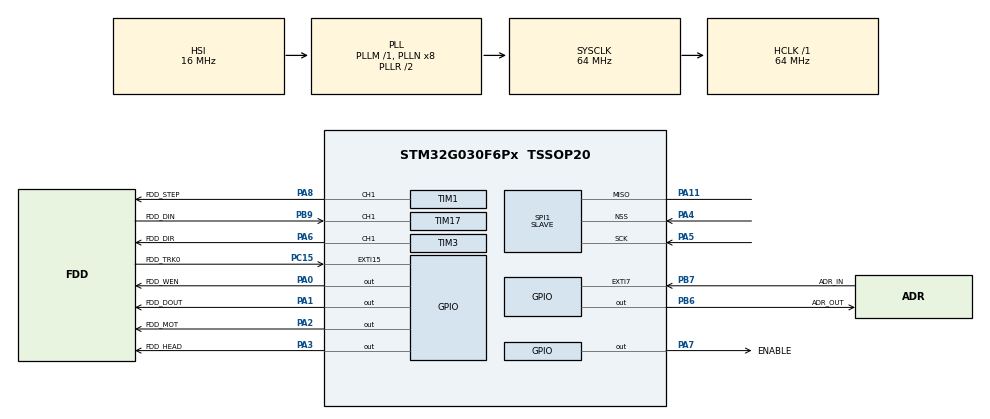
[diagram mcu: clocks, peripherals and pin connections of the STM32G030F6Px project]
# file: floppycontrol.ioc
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Dma.MEMTOMEM.3.Direction=DMA_MEMORY_TO_MEMORY
Dma.MEMTOMEM.3.EventEnable=DISABLE
Dma.MEMTOMEM.3.Instance=DMA1_Channel4
Dma.MEMTOMEM.3.MemDataAlignment=DMA_MDATAALIGN_BYTE
Dma.MEMTOMEM.3.MemInc=DMA_MINC_ENABLE
Dma.MEMTOMEM.3.Mode=DMA_NORMAL
Dma.MEMTOMEM.3.PeriphDataAlignment=DMA_PDATAALIGN_BYTE
Dma.MEMTOMEM.3.PeriphInc=DMA_PINC_ENABLE
Dma.MEMTOMEM.3.Polarity=HAL_DMAMUX_REQ_GEN_RISING
Dma.MEMTOMEM.3.Priority=DMA_PRIORITY_LOW
Dma.MEMTOMEM.3.RequestNumber=1
Dma.MEMTOMEM.3.SignalID=NONE
Dma.MEMTOMEM.3.SyncEnable=DISABLE
Dma.MEMTOMEM.3.SyncPolarity=HAL_DMAMUX_SYNC_NO_EVENT
Dma.MEMTOMEM.3.SyncRequestNumber=1
Dma.MEMTOMEM.3.SyncSignalID=NONE
Dma.Request0=SPI1_RX
Dma.Request1=SPI1_TX
Dma.Request2=TIM17_CH1
Dma.Request3=MEMTOMEM
Dma.SPI1_RX.0.Direction=DMA_PERIPH_TO_MEMORY
Dma.SPI1_RX.0.EventEnable=DISABLE
Dma.SPI1_RX.0.Instance=DMA1_Channel1
Dma.SPI1_RX.0.MemDataAlignment=DMA_MDATAALIGN_BYTE
Dma.SPI1_RX.0.MemInc=DMA_MINC_ENABLE
Dma.SPI1_RX.0.Mode=DMA_NORMAL
Dma.SPI1_RX.0.PeriphDataAlignment=DMA_PDATAALIGN_BYTE
Dma.SPI1_RX.0.PeriphInc=DMA_PINC_DISABLE
Dma.SPI1_RX.0.Polarity=HAL_DMAMUX_REQ_GEN_RISING
Dma.SPI1_RX.0.Priority=DMA_PRIORITY_LOW
Dma.SPI1_RX.0.RequestNumber=1
Dma.SPI1_RX.0.SignalID=NONE
Dma.SPI1_RX.0.SyncEnable=DISABLE
Dma.SPI1_RX.0.SyncPolarity=HAL_DMAMUX_SYNC_NO_EVENT
Dma.SPI1_RX.0.SyncRequestNumber=1
Dma.SPI1_RX.0.SyncSignalID=NONE
Dma.SPI1_TX.1.Direction=DMA_MEMORY_TO_PERIPH
Dma.SPI1_TX.1.EventEnable=DISABLE
Dma.SPI1_TX.1.Instance=DMA1_Channel2
Dma.SPI1_TX.1.MemDataAlignment=DMA_MDATAALIGN_BYTE
Dma.SPI1_TX.1.MemInc=DMA_MINC_ENABLE
Dma.SPI1_TX.1.Mode=DMA_NORMAL
Dma.SPI1_TX.1.PeriphDataAlignment=DMA_PDATAALIGN_BYTE
Dma.SPI1_TX.1.PeriphInc=DMA_PINC_DISABLE
Dma.SPI1_TX.1.Polarity=HAL_DMAMUX_REQ_GEN_RISING
Dma.SPI1_TX.1.Priority=DMA_PRIORITY_LOW
Dma.SPI1_TX.1.RequestNumber=1
Dma.SPI1_TX.1.SignalID=NONE
Dma.SPI1_TX.1.SyncEnable=DISABLE
Dma.SPI1_TX.1.SyncPolarity=HAL_DMAMUX_SYNC_NO_EVENT
Dma.SPI1_TX.1.SyncRequestNumber=1
Dma.SPI1_TX.1.SyncSignalID=NONE
Dma.TIM17_CH1.2.Direction=DMA_PERIPH_TO_MEMORY
Dma.TIM17_CH1.2.EventEnable=DISABLE
Dma.TIM17_CH1.2.Instance=DMA1_Channel3
Dma.TIM17_CH1.2.MemDataAlignment=DMA_MDATAALIGN_HALFWORD
Dma.TIM17_CH1.2.MemInc=DMA_MINC_ENABLE
Dma.TIM17_CH1.2.Mode=DMA_CIRCULAR
Dma.TIM17_CH1.2.PeriphDataAlignment=DMA_PDATAALIGN_HALFWORD
Dma.TIM17_CH1.2.PeriphInc=DMA_PINC_DISABLE
Dma.TIM17_CH1.2.Polarity=HAL_DMAMUX_REQ_GEN_RISING
Dma.TIM17_CH1.2.Priority=DMA_PRIORITY_LOW
Dma.TIM17_CH1.2.RequestNumber=1
Dma.TIM17_CH1.2.SignalID=NONE
Dma.TIM17_CH1.2.SyncEnable=DISABLE
Dma.TIM17_CH1.2.SyncPolarity=HAL_DMAMUX_SYNC_NO_EVENT
Dma.TIM17_CH1.2.SyncRequestNumber=1
Dma.TIM17_CH1.2.SyncSignalID=NONE
Mcu.Family=STM32G0
Mcu.Name=STM32G030F6Px
Mcu.Package=TSSOP20
NVIC.DMA1_Channel1_IRQn=true\:0\:0\:false\:false\:true\:false\:true\:true
NVIC.DMA1_Channel2_3_IRQn=true\:1\:0\:true\:false\:true\:false\:true\:true
NVIC.EXTI4_15_IRQn=true\:2\:0\:true\:false\:true\:true\:true\:true
NVIC.SPI1_IRQn=true\:1\:0\:true\:false\:true\:true\:true\:true
NVIC.TIM17_IRQn=true\:2\:0\:true\:false\:true\:true\:true\:true
PA0.GPIO_Label=FDD_WEN
PA0.GPIO_ModeDefaultOutputPP=GPIO_MODE_OUTPUT_OD
PA0.GPIO_PuPd=GPIO_NOPULL
PA0.PinState=GPIO_PIN_SET
PA0.Signal=GPIO_Output
PA1.GPIO_Label=FDD_DOUT
PA1.GPIO_ModeDefaultOutputPP=GPIO_MODE_OUTPUT_OD
PA1.GPIO_PuPd=GPIO_NOPULL
PA1.PinState=GPIO_PIN_SET
PA1.Signal=GPIO_Output
PA11\ [PA9].GPIO_Speed=GPIO_SPEED_FREQ_HIGH
PA11\ [PA9].Mode=Simplex_Bidirectional_Slave
PA11\ [PA9].Signal=SPI1_MISO
PA12\ [PA10].GPIO_Label=EXTCLK
PA12\ [PA10].Signal=S_TIM1_ETR
PA13.GPIO_Label=SWD_IDX
PA13.Mode=Serial_Wire
PA13.Signal=SYS_SWDIO
PA14-BOOT0.Mode=Serial_Wire
PA14-BOOT0.Signal=SYS_SWCLK
PA14-BOOT0__PA15.StandardMode=false
PA2.GPIO_Label=FDD_MOT
PA2.GPIO_ModeDefaultOutputPP=GPIO_MODE_OUTPUT_OD
PA2.GPIO_PuPd=GPIO_NOPULL
PA2.PinState=GPIO_PIN_SET
PA2.Signal=GPIO_Output
PA3.GPIO_Label=FDD_HEAD
PA3.GPIO_ModeDefaultOutputPP=GPIO_MODE_OUTPUT_OD
PA3.GPIO_PuPd=GPIO_NOPULL
PA3.PinState=GPIO_PIN_SET
PA3.Signal=GPIO_Output
PA4.GPIO_Speed=GPIO_SPEED_FREQ_HIGH
PA4.Mode=NSS_Signal_Hard_Input
PA4.Signal=SPI1_NSS
PA5.GPIO_Speed=GPIO_SPEED_FREQ_HIGH
PA5.Mode=Simplex_Bidirectional_Slave
PA5.Signal=SPI1_SCK
PA6.GPIO_Label=FDD_DIR
PA6.GPIO_ModeDefaultPP=GPIO_MODE_AF_OD
PA6.GPIO_Speed=GPIO_SPEED_FREQ_HIGH
PA6.Signal=S_TIM3_CH1
PA7.GPIO_Label=ENABLE
PA7.GPIO_ModeDefaultOutputPP=GPIO_MODE_OUTPUT_OD
PA7.GPIO_PuPd=GPIO_PULLUP
PA7.GPIO_Speed=GPIO_SPEED_FREQ_HIGH
PA7.PinState=GPIO_PIN_SET
PA7.Signal=GPIO_Output
PA8.GPIO_Label=FDD_STEP
PA8.GPIO_ModeDefaultPP=GPIO_MODE_AF_OD
PA8.GPIO_Speed=GPIO_SPEED_FREQ_HIGH
PA8.PinState=GPIO_PIN_RESET
PA8.Signal=S_TIM1_CH1
PB0__PB1__PB2__PA8.StandardMode=true
PB3__PB4__PB5__PB6.StandardMode=true
PB6.GPIO_Label=ADR_OUT
PB6.GPIO_Speed=GPIO_SPEED_FREQ_MEDIUM
PB6.Signal=GPIO_Output
PB7.GPIO_Label=ADR_IN
PB7.GPIO_ModeDefaultEXTI=GPIO_MODE_IT_RISING_FALLING
PB7.GPIO_PuPd=GPIO_PULLUP
PB7.Signal=GPXTI7
PB7__PB8.StandardMode=true
PB9.GPIO_FM9=SYSCFG_FASTMODEPLUS_PB9
PB9.GPIO_Label=FDD_DIN
PB9.GPIO_ModeDefaultPP=GPIO_MODE_AF_OD
PB9.GPIO_PuPd=GPIO_PULLUP
PB9.Signal=S_TIM17_CH1
PC14-OSC32_IN\ (PC14)__PB9.StandardMode=true
PC15-OSC32_OUT\ (PC15).GPIO_Label=FDD_TRK0
PC15-OSC32_OUT\ (PC15).GPIO_ModeDefaultEXTI=GPIO_MODE_IT_FALLING
PC15-OSC32_OUT\ (PC15).GPIO_PuPd=GPIO_PULLUP
PC15-OSC32_OUT\ (PC15).Signal=GPXTI15
ProjectManager.HeapSize=0x200
ProjectManager.StackSize=0x400
ProjectManager.TargetToolchain=STM32CubeIDE
RCC.ADCFreq_Value=64000000
RCC.AHBFreq_Value=64000000
RCC.CortexFreq_Value=64000000
RCC.EXTERNAL_CLOCK_VALUE=12288000
RCC.HCLKFreq_Value=64000000
RCC.HSE_VALUE=8000000
RCC.HSI_VALUE=16000000
RCC.LSE_VALUE=32768
RCC.SYSCLKFreq_VALUE=64000000
RCC.SYSCLKSource=RCC_SYSCLKSOURCE_PLLCLK
RCC.VCOOutputFreq_Value=128000000
SH.S_TIM17_CH1.0=TIM17_CH1,Input_Capture1_from_TI1
SH.S_TIM1_CH1.0=TIM1_CH1,PWM Generation1 CH1
SH.S_TIM1_ETR.0=TIM1_ETR
SH.S_TIM3_CH1.0=TIM3_CH1,PWM Generation1 CH1
SPI1.CLKPhase=SPI_PHASE_1EDGE
SPI1.CLKPolarity=SPI_POLARITY_LOW
SPI1.CRCCalculation=SPI_CRCCALCULATION_ENABLE
SPI1.CRCLength=SPI_CRC_LENGTH_DATASIZE
SPI1.Direction=SPI_DIRECTION_1LINE
SPI1.FirstBit=SPI_FIRSTBIT_MSB
SPI1.Mode=SPI_MODE_SLAVE
SPI1.VirtualNSS=VM_NSSHARD
SPI1.VirtualType=VM_SLAVE
TIM1.Channel-PWM\ Generation1\ CH1=TIM_CHANNEL_1
TIM1.Period=64000
TIM1.Pulse-PWM\ Generation1\ CH1=5000
TIM1.TIM_MasterOutputTrigger=TIM_TRGO_UPDATE
TIM14.Period=100
TIM14.Prescaler=64000
TIM17.AutoReloadPreload=TIM_AUTORELOAD_PRELOAD_ENABLE
TIM17.Channel=TIM_CHANNEL_1
TIM17.Prescaler=15
TIM3.Channel-PWM\ Generation1\ CH1=TIM_CHANNEL_1
TIM3.OCPolarity_1=TIM_OCPOLARITY_LOW
TIM3.Period=160-1
TIM3.Pulse-PWM\ Generation1\ CH1=80
VP_TIM14_VS_ClockSourceINT.Mode=Enable_Timer
VP_TIM17_VS_ClockSourceINT.Mode=Enable_Timer
VP_TIM1_VS_ClockSourceINT.Mode=Internal
VP_TIM3_VS_ClockSourceITR.Mode=TriggerSource_ITR0
VP_TIM3_VS_ControllerModeClock.Mode=Clock Mode
board=custom

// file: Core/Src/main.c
/* USER CODE BEGIN Header */
/**
  ******************************************************************************
  * @file           : main.c
  * @brief          : Main program body
  ******************************************************************************
  * @attention
  *
  * Copyright (c) 2022 STMicroelectronics.
  * All rights reserved.
  *
  * This software is licensed under terms that can be found in the LICENSE file
  * in the root directory of this software component.
  * If no LICENSE file comes with this software, it is provided AS-IS.
  *
  ******************************************************************************
  */
/* USER CODE END Header */
#include "main.h"

/* USER CODE BEGIN Includes */
#include "floppyctrl.h"
/* USER CODE END Includes */

 SPI_HandleTypeDef hspi1;
DMA_HandleTypeDef hdma_spi1_rx;
DMA_HandleTypeDef hdma_spi1_tx;

TIM_HandleTypeDef htim1;
TIM_HandleTypeDef htim3;
TIM_HandleTypeDef htim14;
TIM_HandleTypeDef htim17;
DMA_HandleTypeDef hdma_tim17_ch1;

DMA_HandleTypeDef hdma_memtomem_dma1_channel4;

void SystemClock_Config(void);
static void MX_GPIO_Init(void);
static void MX_DMA_Init(void);
static void MX_SPI1_Init(void);
static void MX_TIM14_Init(void);
static void MX_TIM17_Init(void);

int main(void)
{

  /* MCU Configuration--------------------------------------------------------*/

  /* Reset of all peripherals, Initializes the Flash interface and the Systick. */
  HAL_Init();

  /* Configure the system clock */
  SystemClock_Config();

  /* USER CODE BEGIN SysInit */
  HAL_Delay(1000); // Allow some time for the debugger
  /* USER CODE END SysInit */

  /* Initialize all configured peripherals */
  MX_GPIO_Init();
  MX_DMA_Init();
  MX_SPI1_Init();
  MX_TIM1_Init();
  MX_TIM3_Init();
  MX_TIM14_Init();
  MX_TIM17_Init();
  /* USER CODE BEGIN 2 */
  // Set DIN pin to pullup
//  GPIO_InitTypeDef GPIO_InitStruct = {0};
//  GPIO_InitStruct.Pin = FDD_DIN_Pin;
//  GPIO_InitStruct.Mode = GPIO_MODE_AF_PP;
//  GPIO_InitStruct.Pull = GPIO_PULLUP;
//  GPIO_InitStruct.Speed = GPIO_SPEED_FREQ_HIGH;
//  HAL_GPIO_Init(FDD_DIN_GPIO_Port, &GPIO_InitStruct);

  // TODO use PA12 as ETR for tim1
  initializeTimers();
  findAddress();
  initializeComms();
  homeHeads();
  /* USER CODE END 2 */

  /* Infinite loop */
  while (1)
  {

    /* USER CODE BEGIN 3 */
	  update();

  }
  /* USER CODE END 3 */
}

void SystemClock_Config(void)
{
  RCC_OscInitTypeDef RCC_OscInitStruct = {0};
  RCC_ClkInitTypeDef RCC_ClkInitStruct = {0};

  /** Configure the main internal regulator output voltage
  */
  HAL_PWREx_ControlVoltageScaling(PWR_REGULATOR_VOLTAGE_SCALE1);

  /** Initializes the RCC Oscillators according to the specified parameters
  * in the RCC_OscInitTypeDef structure.
  */
  RCC_OscInitStruct.OscillatorType = RCC_OSCILLATORTYPE_HSI;
  RCC_OscInitStruct.HSIState = RCC_HSI_ON;
  RCC_OscInitStruct.HSIDiv = RCC_HSI_DIV1;
  RCC_OscInitStruct.HSICalibrationValue = RCC_HSICALIBRATION_DEFAULT;
  RCC_OscInitStruct.PLL.PLLState = RCC_PLL_ON;
  RCC_OscInitStruct.PLL.PLLSource = RCC_PLLSOURCE_HSI;
  RCC_OscInitStruct.PLL.PLLM = RCC_PLLM_DIV1;
  RCC_OscInitStruct.PLL.PLLN = 8;
  RCC_OscInitStruct.PLL.PLLP = RCC_PLLP_DIV2;
  RCC_OscInitStruct.PLL.PLLR = RCC_PLLR_DIV2;
  if (HAL_RCC_OscConfig(&RCC_OscInitStruct) != HAL_OK)
  {
    Error_Handler();
  }

  /** Initializes the CPU, AHB and APB buses clocks
  */
  RCC_ClkInitStruct.ClockType = RCC_CLOCKTYPE_HCLK|RCC_CLOCKTYPE_SYSCLK
                              |RCC_CLOCKTYPE_PCLK1;
  RCC_ClkInitStruct.SYSCLKSource = RCC_SYSCLKSOURCE_PLLCLK;
  RCC_ClkInitStruct.AHBCLKDivider = RCC_SYSCLK_DIV1;
  RCC_ClkInitStruct.APB1CLKDivider = RCC_HCLK_DIV1;

  if (HAL_RCC_ClockConfig(&RCC_ClkInitStruct, FLASH_LATENCY_2) != HAL_OK)
  {
    Error_Handler();
  }
}

static void MX_SPI1_Init(void)
{

  /* SPI1 parameter configuration*/
  hspi1.Instance = SPI1;
  hspi1.Init.Mode = SPI_MODE_SLAVE;
  hspi1.Init.Direction = SPI_DIRECTION_1LINE;
  hspi1.Init.DataSize = SPI_DATASIZE_8BIT;
  hspi1.Init.CLKPolarity = SPI_POLARITY_LOW;
  hspi1.Init.CLKPhase = SPI_PHASE_1EDGE;
  hspi1.Init.NSS = SPI_NSS_HARD_INPUT;
  hspi1.Init.FirstBit = SPI_FIRSTBIT_MSB;
  hspi1.Init.TIMode = SPI_TIMODE_DISABLE;
  hspi1.Init.CRCCalculation = SPI_CRCCALCULATION_ENABLE;
  hspi1.Init.CRCPolynomial = 7;
  hspi1.Init.CRCLength = SPI_CRC_LENGTH_DATASIZE;
  hspi1.Init.NSSPMode = SPI_NSS_PULSE_DISABLE;
  if (HAL_SPI_Init(&hspi1) != HAL_OK)
  {
    Error_Handler();
  }

}

void MX_TIM1_Init(void)
{

  TIM_ClockConfigTypeDef sClockSourceConfig = {0};
  TIM_MasterConfigTypeDef sMasterConfig = {0};
  TIM_OC_InitTypeDef sConfigOC = {0};
  TIM_BreakDeadTimeConfigTypeDef sBreakDeadTimeConfig = {0};

  htim1.Instance = TIM1;
  htim1.Init.Prescaler = 0;
  htim1.Init.CounterMode = TIM_COUNTERMODE_UP;
  htim1.Init.Period = 64000;
  htim1.Init.ClockDivision = TIM_CLOCKDIVISION_DIV1;
  htim1.Init.RepetitionCounter = 0;
  htim1.Init.AutoReloadPreload = TIM_AUTORELOAD_PRELOAD_DISABLE;
  if (HAL_TIM_Base_Init(&htim1) != HAL_OK)
  {
    Error_Handler();
  }
  sClockSourceConfig.ClockSource = TIM_CLOCKSOURCE_INTERNAL;
  if (HAL_TIM_ConfigClockSource(&htim1, &sClockSourceConfig) != HAL_OK)
  {
    Error_Handler();
  }
  if (HAL_TIM_PWM_Init(&htim1) != HAL_OK)
  {
    Error_Handler();
  }
  sMasterConfig.MasterOutputTrigger = TIM_TRGO_UPDATE;
  sMasterConfig.MasterOutputTrigger2 = TIM_TRGO2_RESET;
  sMasterConfig.MasterSlaveMode = TIM_MASTERSLAVEMODE_DISABLE;
  if (HAL_TIMEx_MasterConfigSynchronization(&htim1, &sMasterConfig) != HAL_OK)
  {
    Error_Handler();
  }
  sConfigOC.OCMode = TIM_OCMODE_PWM1;
  sConfigOC.Pulse = 5000;
  sConfigOC.OCPolarity = TIM_OCPOLARITY_HIGH;
  sConfigOC.OCNPolarity = TIM_OCNPOLARITY_HIGH;
  sConfigOC.OCFastMode = TIM_OCFAST_DISABLE;
  sConfigOC.OCIdleState = TIM_OCIDLESTATE_RESET;
  sConfigOC.OCNIdleState = TIM_OCNIDLESTATE_RESET;
  if (HAL_TIM_PWM_ConfigChannel(&htim1, &sConfigOC, TIM_CHANNEL_1) != HAL_OK)
  {
    Error_Handler();
  }
  sBreakDeadTimeConfig.OffStateRunMode = TIM_OSSR_DISABLE;
  sBreakDeadTimeConfig.OffStateIDLEMode = TIM_OSSI_DISABLE;
  sBreakDeadTimeConfig.LockLevel = TIM_LOCKLEVEL_OFF;
  sBreakDeadTimeConfig.DeadTime = 0;
  sBreakDeadTimeConfig.BreakState = TIM_BREAK_DISABLE;
  sBreakDeadTimeConfig.BreakPolarity = TIM_BREAKPOLARITY_HIGH;
  sBreakDeadTimeConfig.BreakFilter = 0;
  sBreakDeadTimeConfig.BreakAFMode = TIM_BREAK_AFMODE_INPUT;
  sBreakDeadTimeConfig.Break2State = TIM_BREAK2_DISABLE;
  sBreakDeadTimeConfig.Break2Polarity = TIM_BREAK2POLARITY_HIGH;
  sBreakDeadTimeConfig.Break2Filter = 0;
  sBreakDeadTimeConfig.Break2AFMode = TIM_BREAK_AFMODE_INPUT;
  sBreakDeadTimeConfig.AutomaticOutput = TIM_AUTOMATICOUTPUT_DISABLE;
  if (HAL_TIMEx_ConfigBreakDeadTime(&htim1, &sBreakDeadTimeConfig) != HAL_OK)
  {
    Error_Handler();
  }
  HAL_TIM_MspPostInit(&htim1);

}

void MX_TIM3_Init(void)
{

  TIM_SlaveConfigTypeDef sSlaveConfig = {0};
  TIM_MasterConfigTypeDef sMasterConfig = {0};
  TIM_OC_InitTypeDef sConfigOC = {0};

  htim3.Instance = TIM3;
  htim3.Init.Prescaler = 0;
  htim3.Init.CounterMode = TIM_COUNTERMODE_UP;
  htim3.Init.Period = 160-1;
  htim3.Init.ClockDivision = TIM_CLOCKDIVISION_DIV1;
  htim3.Init.AutoReloadPreload = TIM_AUTORELOAD_PRELOAD_DISABLE;
  if (HAL_TIM_Base_Init(&htim3) != HAL_OK)
  {
    Error_Handler();
  }
  if (HAL_TIM_PWM_Init(&htim3) != HAL_OK)
  {
    Error_Handler();
  }
  sSlaveConfig.SlaveMode = TIM_SLAVEMODE_EXTERNAL1;
  sSlaveConfig.InputTrigger = TIM_TS_ITR0;
  if (HAL_TIM_SlaveConfigSynchro(&htim3, &sSlaveConfig) != HAL_OK)
  {
    Error_Handler();
  }
  sMasterConfig.MasterOutputTrigger = TIM_TRGO_RESET;
  sMasterConfig.MasterSlaveMode = TIM_MASTERSLAVEMODE_DISABLE;
  if (HAL_TIMEx_MasterConfigSynchronization(&htim3, &sMasterConfig) != HAL_OK)
  {
    Error_Handler();
  }
  sConfigOC.OCMode = TIM_OCMODE_PWM1;
  sConfigOC.Pulse = 80;
  sConfigOC.OCPolarity = TIM_OCPOLARITY_LOW;
  sConfigOC.OCFastMode = TIM_OCFAST_DISABLE;
  if (HAL_TIM_PWM_ConfigChannel(&htim3, &sConfigOC, TIM_CHANNEL_1) != HAL_OK)
  {
    Error_Handler();
  }
  HAL_TIM_MspPostInit(&htim3);

}

static void MX_TIM14_Init(void)
{

  htim14.Instance = TIM14;
  htim14.Init.Prescaler = 64000;
  htim14.Init.CounterMode = TIM_COUNTERMODE_UP;
  htim14.Init.Period = 100;
  htim14.Init.ClockDivision = TIM_CLOCKDIVISION_DIV1;
  htim14.Init.AutoReloadPreload = TIM_AUTORELOAD_PRELOAD_DISABLE;
  if (HAL_TIM_Base_Init(&htim14) != HAL_OK)
  {
    Error_Handler();
  }

}

static void MX_TIM17_Init(void)
{

  TIM_IC_InitTypeDef sConfigIC = {0};

  htim17.Instance = TIM17;
  htim17.Init.Prescaler = 15;
  htim17.Init.CounterMode = TIM_COUNTERMODE_UP;
  htim17.Init.Period = 65535;
  htim17.Init.ClockDivision = TIM_CLOCKDIVISION_DIV1;
  htim17.Init.RepetitionCounter = 0;
  htim17.Init.AutoReloadPreload = TIM_AUTORELOAD_PRELOAD_ENABLE;
  if (HAL_TIM_Base_Init(&htim17) != HAL_OK)
  {
    Error_Handler();
  }
  if (HAL_TIM_IC_Init(&htim17) != HAL_OK)
  {
    Error_Handler();
  }
  sConfigIC.ICPolarity = TIM_INPUTCHANNELPOLARITY_RISING;
  sConfigIC.ICSelection = TIM_ICSELECTION_DIRECTTI;
  sConfigIC.ICPrescaler = TIM_ICPSC_DIV1;
  sConfigIC.ICFilter = 0;
  if (HAL_TIM_IC_ConfigChannel(&htim17, &sConfigIC, TIM_CHANNEL_1) != HAL_OK)
  {
    Error_Handler();
  }

}

static void MX_DMA_Init(void)
{

  /* DMA controller clock enable */
  __HAL_RCC_DMA1_CLK_ENABLE();

  /* Configure DMA request hdma_memtomem_dma1_channel4 on DMA1_Channel4 */
  hdma_memtomem_dma1_channel4.Instance = DMA1_Channel4;
  hdma_memtomem_dma1_channel4.Init.Request = DMA_REQUEST_MEM2MEM;
  hdma_memtomem_dma1_channel4.Init.Direction = DMA_MEMORY_TO_MEMORY;
  hdma_memtomem_dma1_channel4.Init.PeriphInc = DMA_PINC_ENABLE;
  hdma_memtomem_dma1_channel4.Init.MemInc = DMA_MINC_ENABLE;
  hdma_memtomem_dma1_channel4.Init.PeriphDataAlignment = DMA_PDATAALIGN_BYTE;
  hdma_memtomem_dma1_channel4.Init.MemDataAlignment = DMA_MDATAALIGN_BYTE;
  hdma_memtomem_dma1_channel4.Init.Mode = DMA_NORMAL;
  hdma_memtomem_dma1_channel4.Init.Priority = DMA_PRIORITY_LOW;
  if (HAL_DMA_Init(&hdma_memtomem_dma1_channel4) != HAL_OK)
  {
    Error_Handler( );
  }

  /* DMA interrupt init */
  /* DMA1_Channel1_IRQn interrupt configuration */
  HAL_NVIC_SetPriority(DMA1_Channel1_IRQn, 0, 0);
  HAL_NVIC_EnableIRQ(DMA1_Channel1_IRQn);
  /* DMA1_Channel2_3_IRQn interrupt configuration */
  HAL_NVIC_SetPriority(DMA1_Channel2_3_IRQn, 1, 0);
  HAL_NVIC_EnableIRQ(DMA1_Channel2_3_IRQn);

}

static void MX_GPIO_Init(void)
{
  GPIO_InitTypeDef GPIO_InitStruct = {0};

  /* GPIO Ports Clock Enable */
  __HAL_RCC_GPIOB_CLK_ENABLE();
  __HAL_RCC_GPIOC_CLK_ENABLE();
  __HAL_RCC_GPIOA_CLK_ENABLE();

  /*Configure GPIO pin Output Level */
  HAL_GPIO_WritePin(GPIOA, FDD_WEN_Pin|FDD_DOUT_Pin|FDD_MOT_Pin|FDD_HEAD_Pin
                          |ENABLE_Pin, GPIO_PIN_SET);

  /*Configure GPIO pin Output Level */
  HAL_GPIO_WritePin(ADR_OUT_GPIO_Port, ADR_OUT_Pin, GPIO_PIN_RESET);

  /*Configure GPIO pin : ADR_IN_Pin */
  GPIO_InitStruct.Pin = ADR_IN_Pin;
  GPIO_InitStruct.Mode = GPIO_MODE_IT_RISING_FALLING;
  GPIO_InitStruct.Pull = GPIO_PULLUP;
  HAL_GPIO_Init(ADR_IN_GPIO_Port, &GPIO_InitStruct);

  /*Configure GPIO pin : FDD_TRK0_Pin */
  GPIO_InitStruct.Pin = FDD_TRK0_Pin;
  GPIO_InitStruct.Mode = GPIO_MODE_IT_FALLING;
  GPIO_InitStruct.Pull = GPIO_PULLUP;
  HAL_GPIO_Init(FDD_TRK0_GPIO_Port, &GPIO_InitStruct);

  /*Configure GPIO pins : FDD_WEN_Pin FDD_DOUT_Pin FDD_MOT_Pin FDD_HEAD_Pin */
  GPIO_InitStruct.Pin = FDD_WEN_Pin|FDD_DOUT_Pin|FDD_MOT_Pin|FDD_HEAD_Pin;
  GPIO_InitStruct.Mode = GPIO_MODE_OUTPUT_OD;
  GPIO_InitStruct.Pull = GPIO_NOPULL;
  GPIO_InitStruct.Speed = GPIO_SPEED_FREQ_LOW;
  HAL_GPIO_Init(GPIOA, &GPIO_InitStruct);

  /*Configure GPIO pin : ENABLE_Pin */
  GPIO_InitStruct.Pin = ENABLE_Pin;
  GPIO_InitStruct.Mode = GPIO_MODE_OUTPUT_OD;
  GPIO_InitStruct.Pull = GPIO_PULLUP;
  GPIO_InitStruct.Speed = GPIO_SPEED_FREQ_HIGH;
  HAL_GPIO_Init(ENABLE_GPIO_Port, &GPIO_InitStruct);

  /*Configure GPIO pin : ADR_OUT_Pin */
  GPIO_InitStruct.Pin = ADR_OUT_Pin;
  GPIO_InitStruct.Mode = GPIO_MODE_OUTPUT_PP;
  GPIO_InitStruct.Pull = GPIO_NOPULL;
  GPIO_InitStruct.Speed = GPIO_SPEED_FREQ_MEDIUM;
  HAL_GPIO_Init(ADR_OUT_GPIO_Port, &GPIO_InitStruct);

  /* EXTI interrupt init*/
  HAL_NVIC_SetPriority(EXTI4_15_IRQn, 2, 0);
  HAL_NVIC_EnableIRQ(EXTI4_15_IRQn);

}

void Error_Handler(void)
{
  __disable_irq();
  while (1)
  {
  }
}
